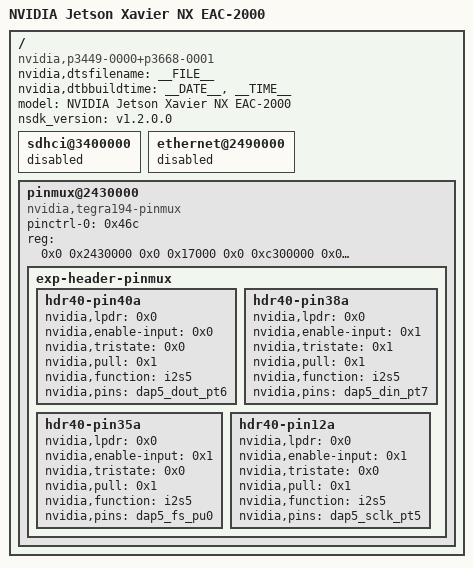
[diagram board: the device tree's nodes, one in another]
/*
 * Top level DTS file for CVM:P3668-0001 and CVB:P3509-0000.
 *
 * Copyright (c) 2021, NVIDIA CORPORATION.  All rights reserved.
 *
 * This program is free software; you can redistribute it and/or modify
 * it under the terms of the GNU General Public License as published by
 * the Free Software Foundation; version 2 of the License.
 *
 * This program is distributed in the hope that it will be useful, but WITHOUT
 * ANY WARRANTY; without even the implied warranty of MERCHANTABILITY or
 * FITNESS FOR A PARTICULAR PURPOSE.  See the GNU General Public License for
 * more details.
 */

/dts-v1/;
#include "common/tegra194-p3668-common.dtsi"
#include "common/tegra194-p3509-0000-a00.dtsi"
#include "common/tegra194-p3668-0001-p3509-0000-nilecam21_two_lane.dtsi"
//#include "common/tegra194-p3668-0001-p3509-0000-camera-imx390-a00_otocam.dtsi"

/ {
	nvidia,dtsfilename = __FILE__;
	nvidia,dtbbuildtime = __DATE__, __TIME__;

	compatible = "nvidia,p3449-0000+p3668-0001", "nvidia,p3509-0000+p3668-0001", "nvidia,tegra194";

	model = "NVIDIA Jetson Xavier NX EAC-2000";
	nsdk_version = "v1.2.0.0";

	sdhci@3400000 {
		status = "disabled";
	};

	/********************** EAC-2000 SETTING **********************/
	/* Disable Navier NX original ethernet port */
	ethernet@2490000 {
		status = "disabled";
	};

	/* Audio i2s0 (CA) <--> dap5 <--> I2S5 (SOM) pin mux change */
	pinmux@2430000 {
		pinctrl-0 = <0x46c>;
		pinctrl-names = "default";
		compatible = "nvidia,tegra194-pinmux";
		reg = <0x0 0x2430000 0x0 0x17000 0x0 0xc300000 0x0 0x4000>;
		status = "okay";
		phandle = <0x299>;

		exp-header-pinmux {
			phandle = <0x46c>;

			hdr40-pin40a {
				nvidia,lpdr = <0x0>;
				nvidia,enable-input = <0x0>;
				nvidia,tristate = <0x0>;
				nvidia,pull = <0x1>;
				nvidia,function = "i2s5";
				nvidia,pins = "dap5_dout_pt6";
			};

			hdr40-pin38a {
				nvidia,lpdr = <0x0>;
				nvidia,enable-input = <0x1>;
				nvidia,tristate = <0x1>;
				nvidia,pull = <0x1>;
				nvidia,function = "i2s5";
				nvidia,pins = "dap5_din_pt7";
			};

			hdr40-pin35a {
				nvidia,lpdr = <0x0>;
				nvidia,enable-input = <0x1>;
				nvidia,tristate = <0x0>;
				nvidia,pull = <0x1>;
				nvidia,function = "i2s5";
				nvidia,pins = "dap5_fs_pu0";
			};

			hdr40-pin12a {
				nvidia,lpdr = <0x0>;
				nvidia,enable-input = <0x1>;
				nvidia,tristate = <0x0>;
				nvidia,pull = <0x1>;
				nvidia,function = "i2s5";
				nvidia,pins = "dap5_sclk_pt5";
			};
		};
	};
	/**************************************************************/
};
